AUTOSAR XML (schema 4-0-3)
standard types defined: Boolean, UInt16, UInt32, UInt8
package /AUTOSAR_Platform/DataConstrs
  range DC_Boolean: raw 0..1
  range DC_UInt16: raw 0..65535
  range DC_UInt8: raw 0..255
package /PATAC/MSM/ComponentTypes
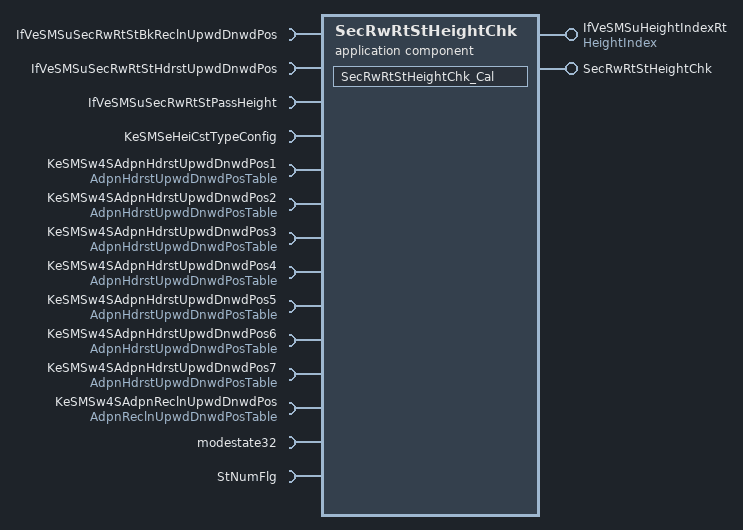
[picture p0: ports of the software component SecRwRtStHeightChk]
  application sw component type SecRwRtStHeightChk
    provide port IfVeSMSuHeightIndexRt: nonqueued-sender-com-spec{data-element=HeightIndex/Val, init-value=0}, provided-interface=HeightIndex
    provide port SecRwRtStHeightChk: server-com-spec{operation=Cal, queue-length=1}, provided-interface=SecRwRtStHeightChk
    14 x require port:
      IfVeSMSuSecRwRtStBkReclnUpwdDnwdPos: nonqueued-receiver-com-spec{data-element=IfVeSMSuSecRwRtStBkReclnUpwdDnwdPos/Val, filter=data-filter-type=ALWAYS, init-value=0}, required-interface=IfVeSMSuSecRwRtStBkReclnUpwdDnwdPos
      IfVeSMSuSecRwRtStHdrstUpwdDnwdPos: nonqueued-receiver-com-spec{data-element=IfVeSMSuSecRwRtStHdrstUpwdDnwdPos/Val, filter=data-filter-type=ALWAYS, init-value=0}, required-interface=IfVeSMSuSecRwRtStHdrstUpwdDnwdPos
      IfVeSMSuSecRwRtStPassHeight: nonqueued-receiver-com-spec{data-element=IfVeSMSuSecRwRtStPassHeight/Val, filter=data-filter-type=ALWAYS, init-value=0}, required-interface=IfVeSMSuSecRwRtStPassHeight
      KeSMSeHeiCstTypeConfig: parameter-require-com-spec{init-value=0, parameter=KeSMSeHeiCstTypeConfig/Val}, required-interface=KeSMSeHeiCstTypeConfig
      KeSMSw4SAdpnHdrstUpwdDnwdPos1: parameter-require-com-spec{init-value=[0, 2136, 2528, 2924, 3276, 3592, 3876], parameter=AdpnHdrstUpwdDnwdPosTable/Val}, required-interface=AdpnHdrstUpwdDnwdPosTable
      KeSMSw4SAdpnHdrstUpwdDnwdPos2: parameter-require-com-spec{init-value=[0, 1744, 2136, 2528, 2924, 3276, 3592], parameter=AdpnHdrstUpwdDnwdPosTable/Val}, required-interface=AdpnHdrstUpwdDnwdPosTable
      KeSMSw4SAdpnHdrstUpwdDnwdPos3: parameter-require-com-spec{init-value=[0, 1524, 1744, 2136, 2528, 2924, 3276], parameter=AdpnHdrstUpwdDnwdPosTable/Val}, required-interface=AdpnHdrstUpwdDnwdPosTable
      KeSMSw4SAdpnHdrstUpwdDnwdPos4: parameter-require-com-spec{init-value=[0, 1232, 1524, 1744, 2136, 2528, 2924], parameter=AdpnHdrstUpwdDnwdPosTable/Val}, required-interface=AdpnHdrstUpwdDnwdPosTable
      KeSMSw4SAdpnHdrstUpwdDnwdPos5: parameter-require-com-spec{init-value=[0, 926, 1232, 1524, 1744, 2136, 2528], parameter=AdpnHdrstUpwdDnwdPosTable/Val}, required-interface=AdpnHdrstUpwdDnwdPosTable
      KeSMSw4SAdpnHdrstUpwdDnwdPos6: parameter-require-com-spec{init-value=[0, 648, 964, 1232, 1524, 1744, 2136], parameter=AdpnHdrstUpwdDnwdPosTable/Val}, required-interface=AdpnHdrstUpwdDnwdPosTable
      KeSMSw4SAdpnHdrstUpwdDnwdPos7: parameter-require-com-spec{init-value=[0, 80, 160, 240, 320, 400, 600], parameter=AdpnHdrstUpwdDnwdPosTable/Val}, required-interface=AdpnHdrstUpwdDnwdPosTable
      KeSMSw4SAdpnReclnUpwdDnwdPos: parameter-require-com-spec{init-value=[1360, 1640, 1916, 2196, 2472, 2752, 3280], parameter=AdpnReclnUpwdDnwdPosTable/Val}, required-interface=AdpnReclnUpwdDnwdPosTable
      modestate32: nonqueued-receiver-com-spec{data-element=modestate32/Val, filter=data-filter-type=ALWAYS, init-value=0}, required-interface=modestate32
      StNumFlg: required-interface=StNumFlg
        required-com-specs:
          data-element=Is4s, filter=data-filter-type=ALWAYS, init-value=0
          data-element=Is6s, filter=data-filter-type=ALWAYS, init-value=0
          data-element=Is6s7s, filter=data-filter-type=ALWAYS, init-value=0
          data-element=Is7s, filter=data-filter-type=ALWAYS, init-value=0
    behavior SecRwRtStHeightChk_InternalBehavior
      operation invoked event OIT_SecRwRtStHeightChk_Cal_SecRwRtStHeightChk_Cal: start-on-event=SecRwRtStHeightChk_Cal, operation=SecRwRtStHeightChk.Cal
      runnable SecRwRtStHeightChk_Cal
        data-receive-point-by-arguments:
          8 x access:
            REC_IfVeSMSuSecRwRtStBkReclnUpwdDnwdPos_Val: accessed-variable=IfVeSMSuSecRwRtStBkReclnUpwdDnwdPos.Val
            REC_IfVeSMSuSecRwRtStHdrstUpwdDnwdPos_Val: accessed-variable=IfVeSMSuSecRwRtStHdrstUpwdDnwdPos.Val
            REC_IfVeSMSuSecRwRtStPassHeight_Val: accessed-variable=IfVeSMSuSecRwRtStPassHeight.Val
            REC_modestate32_Val: accessed-variable=modestate32.Val
            REC_StNumFlg_Is4s: accessed-variable=StNumFlg.Is4s
            REC_StNumFlg_Is6s: accessed-variable=StNumFlg.Is6s
            REC_StNumFlg_Is6s7s: accessed-variable=StNumFlg.Is6s7s
            REC_StNumFlg_Is7s: accessed-variable=StNumFlg.Is7s
        data-send-points:
          access SEND_IfVeSMSuHeightIndexRt_Val: accessed-variable=IfVeSMSuHeightIndexRt.Val
        9 x parameter access:
          PA_KeSMSeHeiCstTypeConfig_Val: accessed-parameter=KeSMSeHeiCstTypeConfig.Val
          PA_KeSMSw4SAdpnHdrstUpwdDnwdPos{1..7}_Val: accessed-parameter=KeSMSw4SAdpnHdrstUpwdDnwdPos{1..7}.Val
          PA_KeSMSw4SAdpnReclnUpwdDnwdPos_Val: accessed-parameter=KeSMSw4SAdpnReclnUpwdDnwdPos.Val
  swc implementation SecRwRtStHeightChk_Implementation: behavior=SecRwRtStHeightChk_InternalBehavior
    code-descriptors:
      code Default: artifact-descriptors=autosar-engineering-object={short-label=Default, category=SWSRC}
package /PATAC/MSM/DataTypes/ImplementationDataTypes
  impl type AdpnReclnUpwdDnwdPosTbl: category=ARRAY, sw-calibration-access=READ-ONLY, type-emitter=RTE
    element Element: array-size=7, array-size-semantics=FIXED-SIZE, implementation-data-type=UInt16
package /PATAC/MSM/ModeAdjust/CalPortInterface
  parameter interface AdpnHdrstUpwdDnwdPosTable
    parameter data prototype Val: sw-calibration-access=READ-WRITE, type=AdpnHdrstUpwdDnwdPosTbl
  parameter interface AdpnReclnUpwdDnwdPosTable
    parameter data prototype Val: sw-calibration-access=READ-WRITE, type=AdpnReclnUpwdDnwdPosTbl
  parameter interface KeSMSeHeiCstTypeConfig
    parameter data prototype Val: sw-calibration-access=READ-WRITE, type=UInt8
package /PATAC/MSM/ModeAdjust/DataType
  impl type AdpnHdrstUpwdDnwdPosTbl: category=ARRAY, sw-calibration-access=READ-ONLY, type-emitter=RTE
    element Element: array-size=7, array-size-semantics=FIXED-SIZE, implementation-data-type=UInt16
package /PATAC/MSM/ModeAdjust/PortInterface
  client server interface SecRwRtStHeightChk
    operation Cal
  4 x sender receiver interface:
    HeightIndex: invalidation-policy{data-element=HeightIndex/Val, handle-invalid=DONT-INVALIDATE}
      data Val: type=UInt8  # 0：under 160 1：160 2：165 3：170 4：175 5：180 6：over 180
    IfVeSMSuSecRwRtStPassHeight: invalidation-policy{data-element=IfVeSMSuSecRwRtStPassHeight/Val, handle-invalid=DONT-INVALIDATE}
      data Val: type=UInt8
    modestate32: invalidation-policy{data-element=modestate32/Val, handle-invalid=DONT-INVALIDATE}
      data Val: type=UInt32
    StNumFlg
      4 x data, all with type=Boolean:
        Is4s
        Is6s
        Is6s7s
        Is7s
      invalidation-policys:
        data-element=Is7s, handle-invalid=DONT-INVALIDATE
        data-element=Is6s, handle-invalid=DONT-INVALIDATE
        data-element=Is4s, handle-invalid=DONT-INVALIDATE
        data-element=Is6s7s, handle-invalid=DONT-INVALIDATE
package /PATAC/MSM/PortInterfaces
  sender receiver interface IfVeSMSuSecRwRtStBkReclnUpwdDnwdPos: invalidation-policy{data-element=IfVeSMSuSecRwRtStBkReclnUpwdDnwdPos/Val, handle-invalid=DONT-INVALIDATE}
    data Val: type=UInt16
  sender receiver interface IfVeSMSuSecRwRtStHdrstUpwdDnwdPos: invalidation-policy{data-element=IfVeSMSuSecRwRtStHdrstUpwdDnwdPos/Val, handle-invalid=DONT-INVALIDATE}
    data Val: type=UInt16
